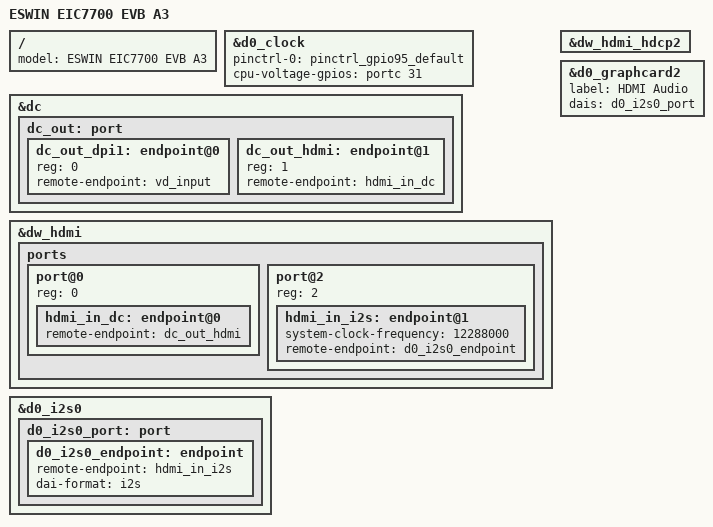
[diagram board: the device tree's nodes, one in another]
// SPDX-License-Identifier: GPL-2.0
/*
 * Device Tree file for Eswin EIC7700 SoC.
 *
 * Copyright 2024, Beijing ESWIN Computing Technology Co., Ltd.. All rights reserved.
 * SPDX-License-Identifier: GPL-2.0
 *
 * This program is free software: you can redistribute it and/or modify
 * it under the terms of the GNU General Public License as published by
 * the Free Software Foundation, version 2.
 *
 * This program is distributed in the hope that it will be useful,
 * but WITHOUT ANY WARRANTY; without even the implied warranty of
 * MERCHANTABILITY or FITNESS FOR A PARTICULAR PURPOSE.  See the
 * GNU General Public License for more details.
 *
 * You should have received a copy of the GNU General Public License
 * along with this program.  If not, see <https://www.gnu.org/licenses/>.
 */
/dts-v1/;

#include "eic7700-evb-a2.dtsi"

/ {
	model = "ESWIN EIC7700 EVB A3";
};

&d0_clock {
	status = "okay";
	pinctrl-names = "default";
	pinctrl-0 = <&pinctrl_gpio95_default>;
	cpu-voltage-gpios = <&portc 31 GPIO_ACTIVE_HIGH>;
};

&dc {
	status = "okay";
	dc_out: port {
		#address-cells = <1>;
		#size-cells = <0>;
		dc_out_dpi1: endpoint@0 {
			reg = <0>;
			remote-endpoint = <&vd_input>;
		};
		dc_out_hdmi: endpoint@1 {
			reg = <1>;
			remote-endpoint = <&hdmi_in_dc>;
		};
	};
};

&dw_hdmi {
	status = "okay";
	ports {
		#address-cells = <1>;
		#size-cells = <0>;
		port@0 {
			reg = <0>;
			hdmi_in_dc: endpoint@0 {
				remote-endpoint = <&dc_out_hdmi>;
			};
		};
		port@2 {
			reg = <2>;
			hdmi_in_i2s: endpoint@1 {
				system-clock-frequency = <12288000>;
				remote-endpoint = <&d0_i2s0_endpoint>;
			};
		};
	};
};

&d0_i2s0 {
	status = "okay";
	d0_i2s0_port: port {
		d0_i2s0_endpoint: endpoint {
			remote-endpoint = <&hdmi_in_i2s>;
			dai-format = "i2s";
		};
	};
};


&dw_hdmi_hdcp2 {
   status = "okay";
};

&d0_graphcard2 {
	status = "okay";
	label = "HDMI Audio";
	dais = <&d0_i2s0_port>;
};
